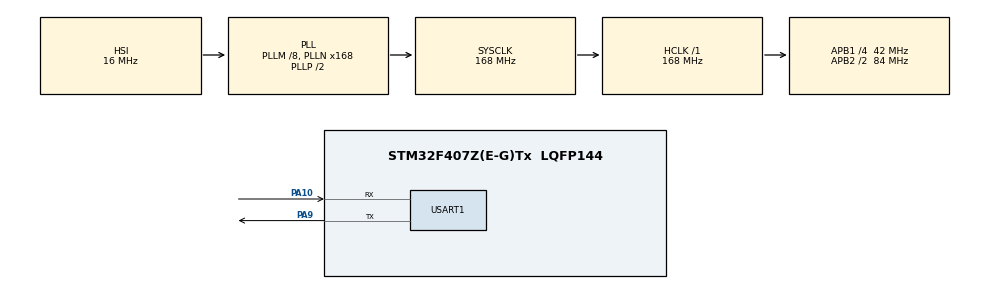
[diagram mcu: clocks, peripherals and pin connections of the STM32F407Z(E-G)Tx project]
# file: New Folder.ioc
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ADC1.Channel-0\#ChannelRegularConversion=ADC_CHANNEL_TEMPSENSOR
ADC1.NbrOfConversionFlag=1
ADC1.Rank-0\#ChannelRegularConversion=1
ADC1.SamplingTime-0\#ChannelRegularConversion=ADC_SAMPLETIME_3CYCLES
ADC1.master=1
Mcu.Family=STM32F4
Mcu.Name=STM32F407Z(E-G)Tx
Mcu.Package=LQFP144
NVIC.ADC_IRQn=true\:0\:0\:false\:false\:true\:true\:true
NVIC.PriorityGroup=NVIC_PRIORITYGROUP_4
NVIC.TIM4_IRQn=true\:0\:0\:false\:false\:true\:true\:true
NVIC.USART1_IRQn=true\:0\:0\:false\:false\:true\:true\:true
PA10.Mode=Asynchronous
PA10.Signal=USART1_RX
PA13.Mode=JTAG_5_pins
PA13.Signal=SYS_JTMS-SWDIO
PA14.Mode=JTAG_5_pins
PA14.Signal=SYS_JTCK-SWCLK
PA15.Mode=JTAG_5_pins
PA15.Signal=SYS_JTDI
PA9.Mode=Asynchronous
PA9.Signal=USART1_TX
PB3.Mode=JTAG_5_pins
PB3.Signal=SYS_JTDO-SWO
PB4.Mode=JTAG_5_pins
PB4.Signal=SYS_JTRST
PC14-OSC32_IN.Mode=LSE-External-Oscillator
PC14-OSC32_IN.Signal=RCC_OSC32_IN
PC15-OSC32_OUT.Mode=LSE-External-Oscillator
PC15-OSC32_OUT.Signal=RCC_OSC32_OUT
PH0-OSC_IN.Mode=HSE-External-Oscillator
PH0-OSC_IN.Signal=RCC_OSC_IN
PH1-OSC_OUT.Mode=HSE-External-Oscillator
PH1-OSC_OUT.Signal=RCC_OSC_OUT
ProjectManager.HeapSize=0x200
ProjectManager.StackSize=0x400
ProjectManager.TargetToolchain=MDK-ARM V5
RCC.48MHZClocksFreq_Value=84000000
RCC.AHBFreq_Value=168000000
RCC.APB1CLKDivider=RCC_HCLK_DIV4
RCC.APB1Freq_Value=42000000
RCC.APB1TimFreq_Value=84000000
RCC.APB2CLKDivider=RCC_HCLK_DIV2
RCC.APB2Freq_Value=84000000
RCC.APB2TimFreq_Value=168000000
RCC.CortexFreq_Value=168000000
RCC.HCLKFreq_Value=168000000
RCC.HSE_VALUE=25000000
RCC.HSI_VALUE=16000000
RCC.PLLM=8
RCC.PLLN=168
RCC.SYSCLKFreq_VALUE=168000000
RCC.SYSCLKSource=RCC_SYSCLKSOURCE_PLLCLK
RCC.VCOOutputFreq_Value=336000000
TIM4.AutoReloadPreload=TIM_AUTORELOAD_PRELOAD_ENABLE
TIM4.Period=1000
TIM4.Prescaler=168
USART1.VirtualMode=VM_ASYNC
VP_ADC1_TempSens_Input.Mode=IN-TempSens
VP_TIM4_VS_ClockSourceINT.Mode=Internal
board=custom

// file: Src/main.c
#include "main.h"
#include "adc.h"
#include "tim.h"
#include "usart.h"
#include "gpio.h"

#include "string.h"
#include "temperature.h"

void SystemClock_Config(void);

uint8_t tx_buff[50] = {0};
uint8_t hello1[] = "Hello World\r\n";
uint8_t hello2[] = "11111111111\r\n";
int main(void)
{
    HAL_Init();

    SystemClock_Config();

    MX_GPIO_Init();
    MX_ADC1_Init();
    MX_TIM4_Init();
    MX_USART1_UART_Init();

    /* Infinite loop */
    /* USER CODE BEGIN WHILE */

    //memcpy(tx_buff, hello1, sizeof(hello1));
    //strcat((char *)tx_buff, "\r\n");

    while (1)
    {

        if(gTaskReg.TaskCnt0 == 0)
        {
            gTaskReg.TaskCnt0 = TASK_200ms;

			gTempReg.val = get_temp();

            HAL_GPIO_TogglePin(GPIOF, GPIO_PIN_9);
            HAL_GPIO_TogglePin(GPIOF, GPIO_PIN_10);
        }
        if(gTaskReg.TaskCnt1 == 0)
        {
            gTaskReg.TaskCnt1 = TASK_1000ms;
            HAL_UART_Transmit(&huart1, hello1, sizeof(hello1), 100);
            HAL_UART_Transmit(&huart1, hello2, sizeof(hello2), 100);

        }
        /* USER CODE END WHILE */

    }
}

void SystemClock_Config(void)
{
    RCC_OscInitTypeDef RCC_OscInitStruct = {0};
    RCC_ClkInitTypeDef RCC_ClkInitStruct = {0};

    /** Configure the main internal regulator output voltage
    */
    __HAL_RCC_PWR_CLK_ENABLE();
    __HAL_PWR_VOLTAGESCALING_CONFIG(PWR_REGULATOR_VOLTAGE_SCALE1);
    /** Initializes the CPU, AHB and APB busses clocks
    */
    RCC_OscInitStruct.OscillatorType = RCC_OSCILLATORTYPE_HSI;
    RCC_OscInitStruct.HSIState = RCC_HSI_ON;
    RCC_OscInitStruct.HSICalibrationValue = RCC_HSICALIBRATION_DEFAULT;
    RCC_OscInitStruct.PLL.PLLState = RCC_PLL_ON;
    RCC_OscInitStruct.PLL.PLLSource = RCC_PLLSOURCE_HSI;
    RCC_OscInitStruct.PLL.PLLM = 8;
    RCC_OscInitStruct.PLL.PLLN = 168;
    RCC_OscInitStruct.PLL.PLLP = RCC_PLLP_DIV2;
    RCC_OscInitStruct.PLL.PLLQ = 4;
    if (HAL_RCC_OscConfig(&RCC_OscInitStruct) != HAL_OK)
    {
        Error_Handler();
    }
    /** Initializes the CPU, AHB and APB busses clocks
    */
    RCC_ClkInitStruct.ClockType = RCC_CLOCKTYPE_HCLK|RCC_CLOCKTYPE_SYSCLK
                                  |RCC_CLOCKTYPE_PCLK1|RCC_CLOCKTYPE_PCLK2;
    RCC_ClkInitStruct.SYSCLKSource = RCC_SYSCLKSOURCE_PLLCLK;
    RCC_ClkInitStruct.AHBCLKDivider = RCC_SYSCLK_DIV1;
    RCC_ClkInitStruct.APB1CLKDivider = RCC_HCLK_DIV4;
    RCC_ClkInitStruct.APB2CLKDivider = RCC_HCLK_DIV2;

    if (HAL_RCC_ClockConfig(&RCC_ClkInitStruct, FLASH_LATENCY_5) != HAL_OK)
    {
        Error_Handler();
    }
}

void Error_Handler(void)
{
}

/************************ (C) COPYRIGHT STMicroelectronics *****END OF FILE****/
